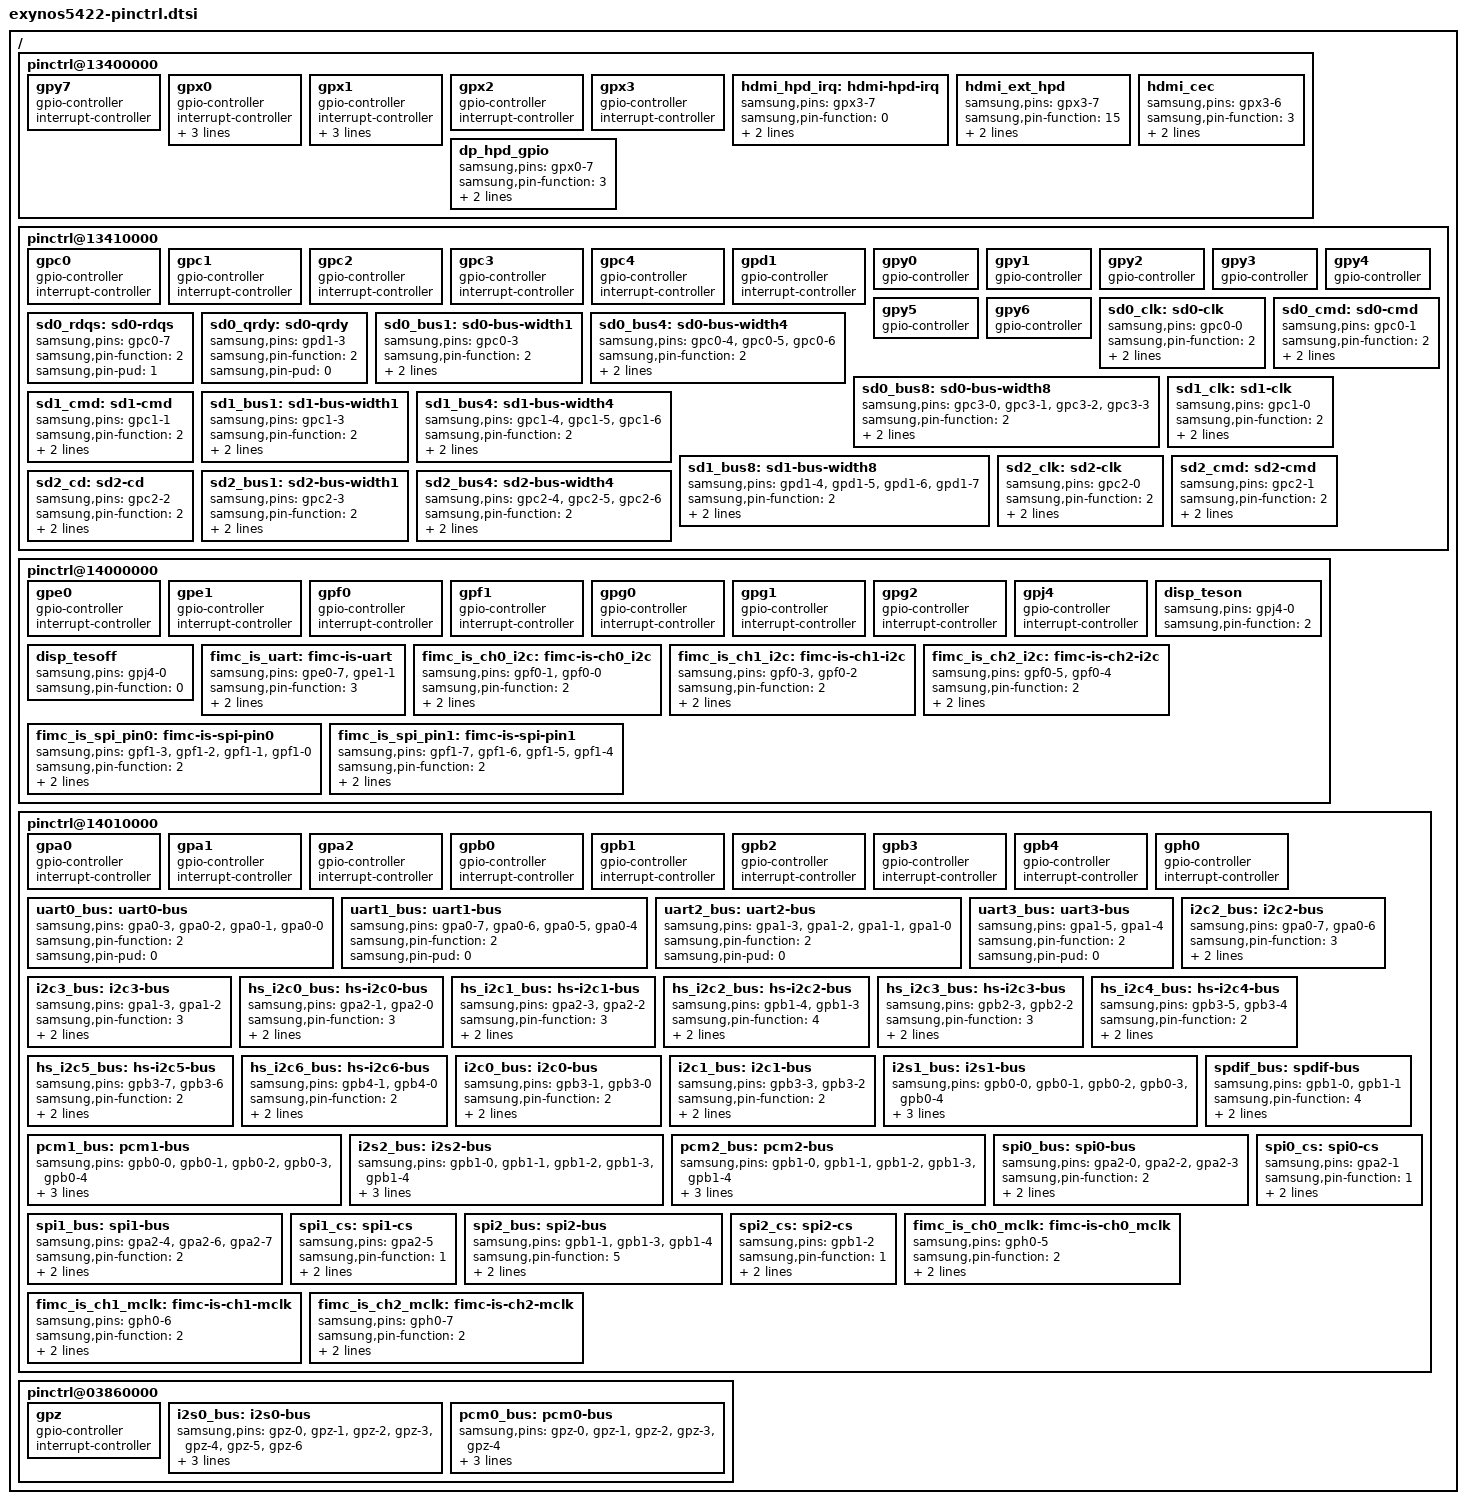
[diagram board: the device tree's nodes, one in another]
/*
 * Samsung's Exynos5422 SoC pin-mux and pin-config device tree source
 *
 * Copyright (c) 2013 Samsung Electronics Co., Ltd.
 *		http://www.samsung.com
 *
 * Samsung's Exynos5422 SoC pin-mux and pin-config options are listed as device
 * tree nodes are listed in this file.
 *
 * This program is free software; you can redistribute it and/or modify
 * it under the terms of the GNU General Public License version 2 as
 * published by the Free Software Foundation.
*/

/ {
	pinctrl@13400000 {
		gpy7: gpy7 {
			gpio-controller;
			#gpio-cells = <2>;

			interrupt-controller;
			#interrupt-cells = <2>;
		};

		gpx0: gpx0 {
			gpio-controller;
			#gpio-cells = <2>;

			interrupt-controller;
			interrupt-parent = <&combiner>;
			#interrupt-cells = <2>;
			interrupts = <23 0>, <24 0>, <25 0>, <25 1>,
				     <26 0>, <26 1>, <27 0>, <27 1>;
		};

		gpx1: gpx1 {
			gpio-controller;
			#gpio-cells = <2>;

			interrupt-controller;
			interrupt-parent = <&combiner>;
			#interrupt-cells = <2>;
			interrupts = <28 0>, <28 1>, <29 0>, <29 1>,
				     <30 0>, <30 1>, <31 0>, <31 1>;
		};

		gpx2: gpx2 {
			gpio-controller;
			#gpio-cells = <2>;

			interrupt-controller;
			#interrupt-cells = <2>;
		};

		gpx3: gpx3 {
			gpio-controller;
			#gpio-cells = <2>;

			interrupt-controller;
			#interrupt-cells = <2>;
		};

		hdmi_hpd_irq: hdmi-hpd-irq {
			samsung,pins = "gpx3-7";
			samsung,pin-function = <0>;
			samsung,pin-pud = <1>;
			samsung,pin-drv = <0>;
		};

		hdmi_ext_hpd: hdmi_ext_hpd {
			samsung,pins = "gpx3-7";
			samsung,pin-function = <15>;
			samsung,pin-pud = <1>;
			samsung,pin-drv = <0>;
		};

		hdmi_cec: hdmi_cec {
			samsung,pins = "gpx3-6";
			samsung,pin-function = <3>;
			samsung,pin-pud = <0>;
			samsung,pin-drv = <3>;
		};

        dp_hpd_gpio: dp_hpd_gpio  {
            samsung,pins = "gpx0-7";
            samsung,pin-function = <3>;
            samsung,pin-pud = <0>;
            samaung,pin-drv = <0>;
        };
	};

	pinctrl@13410000 {
		gpc0: gpc0 {
			gpio-controller;
			#gpio-cells = <2>;

			interrupt-controller;
			#interrupt-cells = <2>;
		};

		gpc1: gpc1 {
			gpio-controller;
			#gpio-cells = <2>;

			interrupt-controller;
			#interrupt-cells = <2>;
		};

		gpc2: gpc2 {
			gpio-controller;
			#gpio-cells = <2>;

			interrupt-controller;
			#interrupt-cells = <2>;
		};

		gpc3: gpc3 {
			gpio-controller;
			#gpio-cells = <2>;

			interrupt-controller;
			#interrupt-cells = <2>;
		};

		gpc4: gpc4 {
			gpio-controller;
			#gpio-cells = <2>;

			interrupt-controller;
			#interrupt-cells = <2>;
		};

		gpd1: gpd1 {
			gpio-controller;
			#gpio-cells = <2>;

			interrupt-controller;
			#interrupt-cells = <2>;
		};

		gpy0: gpy0 {
			gpio-controller;
			#gpio-cells = <2>;
		};

		gpy1: gpy1 {
			gpio-controller;
			#gpio-cells = <2>;
		};

		gpy2: gpy2 {
			gpio-controller;
			#gpio-cells = <2>;
		};

		gpy3: gpy3 {
			gpio-controller;
			#gpio-cells = <2>;
		};

		gpy4: gpy4 {
			gpio-controller;
			#gpio-cells = <2>;
		};

		gpy5: gpy5 {
			gpio-controller;
			#gpio-cells = <2>;
		};

		gpy6: gpy6 {
			gpio-controller;
			#gpio-cells = <2>;
		};

		sd0_clk: sd0-clk {
			samsung,pins = "gpc0-0";
			samsung,pin-function = <2>;
			samsung,pin-pud = <0>;
			samsung,pin-drv = <1>;
		};

		sd0_cmd: sd0-cmd {
			samsung,pins = "gpc0-1";
			samsung,pin-function = <2>;
			samsung,pin-pud = <0>;
			samsung,pin-drv = <1>;
		};

		sd0_rdqs: sd0-rdqs {
			samsung,pins = "gpc0-7";
			samsung,pin-function = <2>;
			samsung,pin-pud = <1>;
		};

		sd0_qrdy: sd0-qrdy {
			samsung,pins = "gpd1-3";
			samsung,pin-function = <2>;
			samsung,pin-pud = <0>;
		};

		sd0_bus1: sd0-bus-width1 {
			samsung,pins = "gpc0-3";
			samsung,pin-function = <2>;
			samsung,pin-pud = <3>;
			samsung,pin-drv = <1>;
		};

		sd0_bus4: sd0-bus-width4 {
			samsung,pins = "gpc0-4", "gpc0-5", "gpc0-6";
			samsung,pin-function = <2>;
			samsung,pin-pud = <3>;
			samsung,pin-drv = <1>;
		};

		sd0_bus8: sd0-bus-width8 {
			samsung,pins = "gpc3-0", "gpc3-1", "gpc3-2", "gpc3-3";
			samsung,pin-function = <2>;
			samsung,pin-pud = <3>;
			samsung,pin-drv = <1>;
		};

		sd1_clk: sd1-clk {
			samsung,pins = "gpc1-0";
			samsung,pin-function = <2>;
			samsung,pin-pud = <0>;
			samsung,pin-drv = <1>;
		};

		sd1_cmd: sd1-cmd {
			samsung,pins = "gpc1-1";
			samsung,pin-function = <2>;
			samsung,pin-pud = <0>;
			samsung,pin-drv = <1>;
		};

		sd1_bus1: sd1-bus-width1 {
			samsung,pins = "gpc1-3";
			samsung,pin-function = <2>;
			samsung,pin-pud = <3>;
			samsung,pin-drv = <1>;
		};

		sd1_bus4: sd1-bus-width4 {
			samsung,pins = "gpc1-4", "gpc1-5", "gpc1-6";
			samsung,pin-function = <2>;
			samsung,pin-pud = <3>;
			samsung,pin-drv = <1>;
		};

		sd1_bus8: sd1-bus-width8 {
			samsung,pins = "gpd1-4", "gpd1-5", "gpd1-6", "gpd1-7";
			samsung,pin-function = <2>;
			samsung,pin-pud = <3>;
			samsung,pin-drv = <1>;
		};

		sd2_clk: sd2-clk {
			samsung,pins = "gpc2-0";
			samsung,pin-function = <2>;
			samsung,pin-pud = <0>;
			samsung,pin-drv = <1>;
		};

		sd2_cmd: sd2-cmd {
			samsung,pins = "gpc2-1";
			samsung,pin-function = <2>;
			samsung,pin-pud = <0>;
			samsung,pin-drv = <1>;
		};

		sd2_cd: sd2-cd {
			samsung,pins = "gpc2-2";
			samsung,pin-function = <2>;
			samsung,pin-pud = <3>;
			samsung,pin-drv = <1>;
		};

		sd2_bus1: sd2-bus-width1 {
			samsung,pins = "gpc2-3";
			samsung,pin-function = <2>;
			samsung,pin-pud = <3>;
			samsung,pin-drv = <1>;
		};

		sd2_bus4: sd2-bus-width4 {
			samsung,pins = "gpc2-4", "gpc2-5", "gpc2-6";
			samsung,pin-function = <2>;
			samsung,pin-pud = <3>;
			samsung,pin-drv = <1>;
		};
	};

	pinctrl@14000000 {
		gpe0: gpe0 {
			gpio-controller;
			#gpio-cells = <2>;

			interrupt-controller;
			#interrupt-cells = <2>;
		};

		gpe1: gpe1 {
			gpio-controller;
			#gpio-cells = <2>;

			interrupt-controller;
			#interrupt-cells = <2>;
		};

		gpf0: gpf0 {
			gpio-controller;
			#gpio-cells = <2>;

			interrupt-controller;
			#interrupt-cells = <2>;
		};

		gpf1: gpf1 {
			gpio-controller;
			#gpio-cells = <2>;

			interrupt-controller;
			#interrupt-cells = <2>;
		};

		gpg0: gpg0 {
			gpio-controller;
			#gpio-cells = <2>;

			interrupt-controller;
			#interrupt-cells = <2>;
		};

		gpg1: gpg1 {
			gpio-controller;
			#gpio-cells = <2>;

			interrupt-controller;
			#interrupt-cells = <2>;
		};

		gpg2: gpg2 {
			gpio-controller;
			#gpio-cells = <2>;

			interrupt-controller;
			#interrupt-cells = <2>;
		};

		gpj4: gpj4 {
			gpio-controller;
			#gpio-cells = <2>;

			interrupt-controller;
			#interrupt-cells = <2>;
		};

		disp_teson: disp_teson {
			samsung,pins = "gpj4-0";
			samsung,pin-function = <2>;
		};

		disp_tesoff: disp_tesoff {
			samsung,pins = "gpj4-0";
			samsung,pin-function = <0>;
		};

		fimc_is_uart: fimc-is-uart {
			samsung,pins = "gpe0-7", "gpe1-1";
			samsung,pin-function = <3>;
			samsung,pin-pud = <0>;
			samsung,pin-drv = <0>;
		};

		fimc_is_ch0_i2c: fimc-is-ch0_i2c {
			samsung,pins = "gpf0-1", "gpf0-0";
			samsung,pin-function = <2>;
			samsung,pin-pud = <0>;
			samsung,pin-drv = <0>;
		};

		fimc_is_ch1_i2c: fimc-is-ch1-i2c {
			samsung,pins = "gpf0-3", "gpf0-2";
			samsung,pin-function = <2>;
			samsung,pin-pud = <0>;
			samsung,pin-drv = <0>;
		};

		fimc_is_ch2_i2c: fimc-is-ch2-i2c {
			samsung,pins = "gpf0-5", "gpf0-4";
			samsung,pin-function = <2>;
			samsung,pin-pud = <0>;
			samsung,pin-drv = <0>;
		};

		fimc_is_spi_pin0: fimc-is-spi-pin0 {
			samsung,pins = "gpf1-3", "gpf1-2", "gpf1-1", "gpf1-0";
			samsung,pin-function = <2>;
			samsung,pin-pud = <0>;
			samsung,pin-drv = <0>;
		};

		fimc_is_spi_pin1: fimc-is-spi-pin1 {
			samsung,pins = "gpf1-7", "gpf1-6", "gpf1-5", "gpf1-4";
			samsung,pin-function = <2>;
			samsung,pin-pud = <0>;
			samsung,pin-drv = <0>;
		};
	};

	pinctrl@14010000 {
		gpa0: gpa0 {
			gpio-controller;
			#gpio-cells = <2>;

			interrupt-controller;
			#interrupt-cells = <2>;
		};

		gpa1: gpa1 {
			gpio-controller;
			#gpio-cells = <2>;

			interrupt-controller;
			#interrupt-cells = <2>;
		};

		gpa2: gpa2 {
			gpio-controller;
			#gpio-cells = <2>;

			interrupt-controller;
			#interrupt-cells = <2>;
		};

		gpb0: gpb0 {
			gpio-controller;
			#gpio-cells = <2>;

			interrupt-controller;
			#interrupt-cells = <2>;
		};

		gpb1: gpb1 {
			gpio-controller;
			#gpio-cells = <2>;

			interrupt-controller;
			#interrupt-cells = <2>;
		};

		gpb2: gpb2 {
			gpio-controller;
			#gpio-cells = <2>;

			interrupt-controller;
			#interrupt-cells = <2>;
		};

		gpb3: gpb3 {
			gpio-controller;
			#gpio-cells = <2>;

			interrupt-controller;
			#interrupt-cells = <2>;
		};

		gpb4: gpb4 {
			gpio-controller;
			#gpio-cells = <2>;

			interrupt-controller;
			#interrupt-cells = <2>;
		};

		gph0: gph0 {
			gpio-controller;
			#gpio-cells = <2>;

			interrupt-controller;
			#interrupt-cells = <2>;
		};

		uart0_bus: uart0-bus {
			samsung,pins = "gpa0-3", "gpa0-2", "gpa0-1", "gpa0-0";
			samsung,pin-function = <2>;
			samsung,pin-pud = <0>;
		};

		uart1_bus: uart1-bus {
			samsung,pins = "gpa0-7", "gpa0-6", "gpa0-5", "gpa0-4";
			samsung,pin-function = <2>;
			samsung,pin-pud = <0>;
		};

		uart2_bus: uart2-bus {
			samsung,pins = "gpa1-3", "gpa1-2", "gpa1-1", "gpa1-0";
			samsung,pin-function = <2>;
			samsung,pin-pud = <0>;
		};

		uart3_bus: uart3-bus {
			samsung,pins = "gpa1-5", "gpa1-4";
			samsung,pin-function = <2>;
			samsung,pin-pud = <0>;
		};

		i2c2_bus: i2c2-bus {
			samsung,pins = "gpa0-7", "gpa0-6";
			samsung,pin-function = <3>;
			samsung,pin-pud = <0>;
			samsung,pin-drv = <3>;
		};

		i2c3_bus: i2c3-bus {
			samsung,pins = "gpa1-3", "gpa1-2";
			samsung,pin-function = <3>;
			samsung,pin-pud = <3>;
			samsung,pin-drv = <0>;
		};

		hs_i2c0_bus: hs-i2c0-bus {
			samsung,pins = "gpa2-1", "gpa2-0";
			samsung,pin-function = <3>;
			samsung,pin-pud = <3>;
			samsung,pin-drv = <0>;
		};

		hs_i2c1_bus: hs-i2c1-bus {
			samsung,pins = "gpa2-3", "gpa2-2";
			samsung,pin-function = <3>;
			samsung,pin-pud = <3>;
			samsung,pin-drv = <3>;
		};

		hs_i2c2_bus: hs-i2c2-bus {
			samsung,pins = "gpb1-4", "gpb1-3";
			samsung,pin-function = <4>;
			samsung,pin-pud = <3>;
			samsung,pin-drv = <0>;
		};

		hs_i2c3_bus: hs-i2c3-bus {
			samsung,pins = "gpb2-3", "gpb2-2";
			samsung,pin-function = <3>;
			samsung,pin-pud = <3>;
			samsung,pin-drv = <0>;
		};

		hs_i2c4_bus: hs-i2c4-bus {
			samsung,pins = "gpb3-5", "gpb3-4";
			samsung,pin-function = <2>;
			samsung,pin-pud = <3>;
			samsung,pin-drv = <0>;
		};

		hs_i2c5_bus: hs-i2c5-bus {
			samsung,pins = "gpb3-7", "gpb3-6";
			samsung,pin-function = <2>;
			samsung,pin-pud = <3>;
			samsung,pin-drv = <0>;
		};

		hs_i2c6_bus: hs-i2c6-bus {
			samsung,pins = "gpb4-1", "gpb4-0";
			samsung,pin-function = <2>;
			samsung,pin-pud = <3>;
			samsung,pin-drv = <0>;
		};

		i2c0_bus: i2c0-bus {
			samsung,pins = "gpb3-1", "gpb3-0";
			samsung,pin-function = <2>;
			samsung,pin-pud = <3>;
			samsung,pin-drv = <0>;
		};

		i2c1_bus: i2c1-bus {
			samsung,pins = "gpb3-3", "gpb3-2";
			samsung,pin-function = <2>;
			samsung,pin-pud = <3>;
			samsung,pin-drv = <3>;
		};

		i2s1_bus: i2s1-bus {
			samsung,pins = "gpb0-0", "gpb0-1", "gpb0-2", "gpb0-3",
					"gpb0-4";
			samsung,pin-function = <2>;
			samsung,pin-pud = <1>;
			samsung,pin-drv = <0>;
		};

		pcm1_bus: pcm1-bus {
			samsung,pins = "gpb0-0", "gpb0-1", "gpb0-2", "gpb0-3",
					"gpb0-4";
			samsung,pin-function = <3>;
			samsung,pin-pud = <1>;
			samsung,pin-drv = <0>;
		};

		i2s2_bus: i2s2-bus {
			samsung,pins = "gpb1-0", "gpb1-1", "gpb1-2", "gpb1-3",
					"gpb1-4";
			samsung,pin-function = <2>;
			samsung,pin-pud = <1>;
			samsung,pin-drv = <0>;
		};

		pcm2_bus: pcm2-bus {
			samsung,pins = "gpb1-0", "gpb1-1", "gpb1-2", "gpb1-3",
					"gpb1-4";
			samsung,pin-function = <3>;
			samsung,pin-pud = <1>;
			samsung,pin-drv = <0>;
		};

		spdif_bus: spdif-bus {
			samsung,pins = "gpb1-0", "gpb1-1";
			samsung,pin-function = <4>;
			samsung,pin-pud = <1>;
			samsung,pin-drv = <0>;
		};

		spi0_bus: spi0-bus {
			samsung,pins = "gpa2-0", "gpa2-2", "gpa2-3";
			samsung,pin-function = <2>;
			samsung,pin-pud = <3>;
			samsung,pin-drv = <0>;
		};

		spi0_cs: spi0-cs {
			samsung,pins = "gpa2-1";
			samsung,pin-function = <1>;
			samsung,pin-pud = <2>;
			samsung,pin-drv = <0>;
		};

		spi1_bus: spi1-bus {
			samsung,pins = "gpa2-4", "gpa2-6", "gpa2-7";
			samsung,pin-function = <2>;
			samsung,pin-pud = <3>;
			samsung,pin-drv = <0>;
		};

		spi1_cs: spi1-cs {
			samsung,pins = "gpa2-5";
			samsung,pin-function = <1>;
			samsung,pin-pud = <2>;
			samsung,pin-drv = <0>;
		};

		spi2_bus: spi2-bus {
			samsung,pins = "gpb1-1", "gpb1-3", "gpb1-4";
			samsung,pin-function = <5>;
			samsung,pin-pud = <3>;
			samsung,pin-drv = <0>;
		};

		spi2_cs: spi2-cs {
			samsung,pins = "gpb1-2";
			samsung,pin-function = <1>;
			samsung,pin-pud = <2>;
			samsung,pin-drv = <0>;
		};

		fimc_is_ch0_mclk: fimc-is-ch0_mclk {
			samsung,pins = "gph0-5";
			samsung,pin-function = <2>;
			samsung,pin-pud = <0>;
			samsung,pin-drv = <0>;
		};

		fimc_is_ch1_mclk: fimc-is-ch1-mclk {
			samsung,pins = "gph0-6";
			samsung,pin-function = <2>;
			samsung,pin-pud = <0>;
			samsung,pin-drv = <0>;
		};

		fimc_is_ch2_mclk: fimc-is-ch2-mclk {
			samsung,pins = "gph0-7";
			samsung,pin-function = <2>;
			samsung,pin-pud = <0>;
			samsung,pin-drv = <0>;
		};
	};

	pinctrl@03860000 {
		gpz: gpz {
			gpio-controller;
			#gpio-cells = <2>;

			interrupt-controller;
			#interrupt-cells = <2>;
		};

		i2s0_bus: i2s0-bus {
			samsung,pins = "gpz-0", "gpz-1", "gpz-2", "gpz-3",
					"gpz-4", "gpz-5", "gpz-6";
			samsung,pin-function = <2>;
			samsung,pin-pud = <1>;
			samsung,pin-drv = <0>;
		};

		pcm0_bus: pcm0-bus {
			samsung,pins = "gpz-0", "gpz-1", "gpz-2", "gpz-3",
					"gpz-4";
			samsung,pin-function = <3>;
			samsung,pin-pud = <1>;
			samsung,pin-drv = <0>;
		};
	};
};
